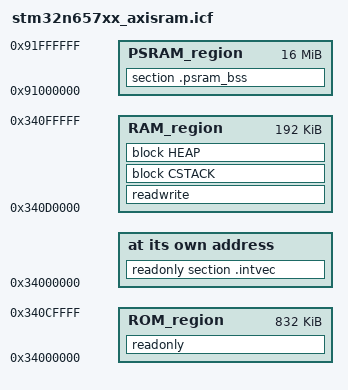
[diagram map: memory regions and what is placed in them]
/*###ICF### Section handled by ICF editor, don't touch! ****/
/*-Editor annotation file-*/
/* IcfEditorFile="$TOOLKIT_DIR$\config\ide\IcfEditor\cortex_v1_0.xml" */
/*-Specials-*/
define symbol __ICFEDIT_intvec_start__ = 0x34000000;
/*-Memory Regions-*/

define symbol __ICFEDIT_region_ROM_start__   = 0x34000000;
define symbol __ICFEDIT_region_ROM_end__     = 0x340CFFFF; /* 832 KB */
define symbol __ICFEDIT_region_RAM_start__   = 0x340D0000;
define symbol __ICFEDIT_region_RAM_end__     = 0x340FFFFF; /* 192 KB */
define symbol __ICFEDIT_region_PSRAM_start__ = 0x91000000;
define symbol __ICFEDIT_region_PSRAM_end__   = 0x91FFFFFF; /* 32 MB */
/*-Sizes-*/
define symbol __ICFEDIT_size_cstack__ = 0x1000; /* 4 KB */
define symbol __ICFEDIT_size_heap__   = 0x400; /* 1 KB */
/**** End of ICF editor section. ###ICF###*/

define memory mem with size = 4G;
define region RAM_region      = mem:[from __ICFEDIT_region_RAM_start__ to __ICFEDIT_region_RAM_end__];
define region ROM_region      = mem:[from __ICFEDIT_region_ROM_start__ to __ICFEDIT_region_ROM_end__];
define region PSRAM_region    = mem:[from __ICFEDIT_region_PSRAM_start__ to __ICFEDIT_region_PSRAM_end__];

define block CSTACK    with alignment = 8, size = __ICFEDIT_size_cstack__   { };
define block HEAP      with alignment = 8, size = __ICFEDIT_size_heap__     { };

initialize by copy { readwrite };
do not initialize  { section .noinit };
do not initialize  { section .psram_bss };

place at address mem:__ICFEDIT_intvec_start__ { readonly section .intvec };

place in ROM_region   { readonly };
place in RAM_region   { readwrite, block CSTACK, block HEAP };
place in PSRAM_region   { section .psram_bss };
